# LVDSRX register map
Vendor: Texas Instruments
Peripheral module from a debugger description file (folder DM50x).
Registers are 32-bit, access per field, reset 0x0 unless marked. A register's access mark holds for its fields unless they carry their own. Offsets are as the file gives them; lines under a group give offsets from that group; [hi:lo] are bit positions; {n}, {i} and the like mark numbered series; 'fields as' and 'values as' point back to an identical list; <NAME> marks a mode.

## LVDSRX
0x00 LVDSRX_REVISION ro reset not defined — IP Revision Identifier (X.Y.R) Used by software to track features, bugs, and compatibility
  [31:0] REVISION — IP Revision
0x10 LVDSRX_SYSCONFIG — Reserved
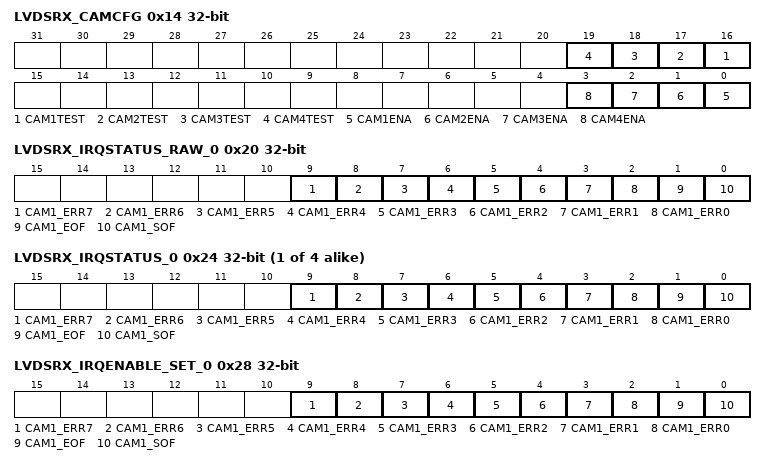
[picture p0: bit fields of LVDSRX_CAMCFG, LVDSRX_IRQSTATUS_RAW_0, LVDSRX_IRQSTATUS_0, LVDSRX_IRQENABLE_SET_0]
0x14 LVDSRX_CAMCFG — Camera port enable
  [all] fields
    0=DIABLE; 1=ENABLE
  [n+15] CAM{n}TEST rw (n=1..4) — Camera port #{n} monitor
  [n-1] CAM{n}ENA rw (n=1..4) — Camera port #{n} control
0x1C LVDSRX_IRQ_EOI — End Of Interrupt number specification
  [2:0] LINE_NUMBER rw — Software End Of Interrupt (EOI) control. Write number of interrupt output to force re-evaluation of associated pending interrupts. Write n: EOI for interrupt output associated with EOI #n.
    0=READ0 (Reads always 0 (no EOI memory)); {v}=EOI{v} (EOI for interrupt output line #{v}) (v=1..4)
0x20 LVDSRX_IRQSTATUS_RAW_0 — Per-event raw interrupt status vector, line #0. Raw status is set even if event is not enabled.
  [all] fields
    0=NOEVENT (No event pending); 1=PENDING (Event pending)
  [9] CAM1_ERR7 rw — sync detected timeout reached
  [8] CAM1_ERR6 rw — CRC error
  [7] CAM1_ERR5 rw — unexpected SOF
  [6] CAM1_ERR4 rw — unexpected SOL
  [5] CAM1_ERR3 rw — unexpected EOF
  [4] CAM1_ERR2 rw — unexpected EOL
  [3] CAM1_ERR1 rw — unexpected SOV
  [2] CAM1_ERR0 rw — EOX not received
  [1] CAM1_EOF rw — End of frame timing
  [0] CAM1_SOF rw — Start of frame timing
{0x24+0x10*i} LVDSRX_IRQSTATUS_{i} (i=0..3) — Per-event 'enabled' interrupt status vector, line #{i}. Enabled status isn't set unless event is enabled.
  [all] fields
    0=NOEVENT (No event pending); 1=PENDING (Event pending)
  [9] CAM{i+1}_ERR7 rw — sync detected timeout reached
  [8] CAM{i+1}_ERR6 rw — CRC error
  [7] CAM{i+1}_ERR5 rw — unexpected SOF
  [6] CAM{i+1}_ERR4 rw — unexpected SOL
  [5] CAM{i+1}_ERR3 rw — unexpected EOF
  [4] CAM{i+1}_ERR2 rw — unexpected EOL
  [3] CAM{i+1}_ERR1 rw — unexpected SOV
  [2] CAM{i+1}_ERR0 rw — EOX not received
  [1] CAM{i+1}_EOF rw — End of frame timing
  [0] CAM{i+1}_SOF rw — Start of frame timing
0x28 LVDSRX_IRQENABLE_SET_0 — Per-event interrupt enable bit vector Write 1 to set (enable interrupt). Readout equal to corresponding _CLR register.
  [all] fields
    0=NOACTION; 1=ENABLED (Interrupt enabled)
  [9] CAM1_ERR7 rw — sync detected timeout reached
  [8] CAM1_ERR6 rw — CRC error
  [7] CAM1_ERR5 rw — unexpected SOF
  [6] CAM1_ERR4 rw — unexpected SOL
  [5] CAM1_ERR3 rw — unexpected EOF
  [4] CAM1_ERR2 rw — unexpected EOL
  [3] CAM1_ERR1 rw — unexpected SOV
  [2] CAM1_ERR0 rw — EOX not received
  [1] CAM1_EOF rw — End of frame timing
  [0] CAM1_SOF rw — Start of frame timing
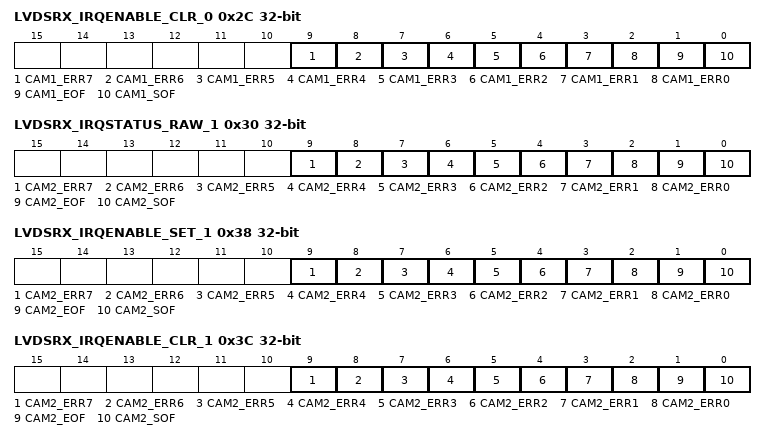
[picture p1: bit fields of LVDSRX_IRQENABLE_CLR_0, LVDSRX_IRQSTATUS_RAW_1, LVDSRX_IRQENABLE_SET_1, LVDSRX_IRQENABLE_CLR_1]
0x2C LVDSRX_IRQENABLE_CLR_0 — Per-event interrupt enable bit vector Write 1 to clear (disable interrupt). Readout equal to corresponding _SET register.
  fields as LVDSRX_IRQENABLE_SET_0
0x30 LVDSRX_IRQSTATUS_RAW_1 — Per-event raw interrupt status vector, line #1. Raw status is set even if event is not enabled.
  [all] fields
    0=NOEVENT (No event pending); 1=PENDING (Event pending)
  [9] CAM2_ERR7 rw — sync detected timeout reached
  [8] CAM2_ERR6 rw — CRC error
  [7] CAM2_ERR5 rw — unexpected SOF
  [6] CAM2_ERR4 rw — unexpected SOL
  [5] CAM2_ERR3 rw — unexpected EOF
  [4] CAM2_ERR2 rw — unexpected EOL
  [3] CAM2_ERR1 rw — unexpected SOV
  [2] CAM2_ERR0 rw — EOX not received
  [1] CAM2_EOF rw — End of frame timing
  [0] CAM2_SOF rw — Start of frame timing
0x38 LVDSRX_IRQENABLE_SET_1 — Per-event interrupt enable bit vector Write 1 to set (enable interrupt). Readout equal to corresponding _CLR register.
  [all] fields
    0=NOACTION; 1=ENABLED (Interrupt enabled)
  [9] CAM2_ERR7 rw — sync detected timeout reached
  [8] CAM2_ERR6 rw — CRC error
  [7] CAM2_ERR5 rw — unexpected SOF
  [6] CAM2_ERR4 rw — unexpected SOL
  [5] CAM2_ERR3 rw — unexpected EOF
  [4] CAM2_ERR2 rw — unexpected EOL
  [3] CAM2_ERR1 rw — unexpected SOV
  [2] CAM2_ERR0 rw — EOX not received
  [1] CAM2_EOF rw — End of frame timing
  [0] CAM2_SOF rw — Start of frame timing
0x3C LVDSRX_IRQENABLE_CLR_1 — Per-event interrupt enable bit vector Write 1 to clear (disable interrupt). Readout equal to corresponding _SET register.
  fields as LVDSRX_IRQENABLE_SET_1
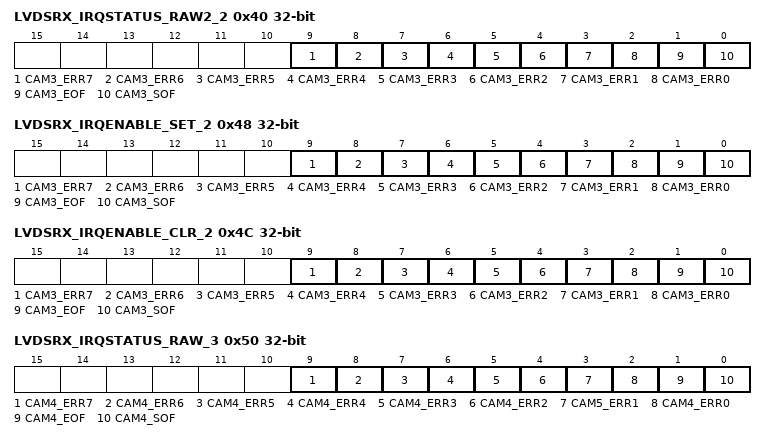
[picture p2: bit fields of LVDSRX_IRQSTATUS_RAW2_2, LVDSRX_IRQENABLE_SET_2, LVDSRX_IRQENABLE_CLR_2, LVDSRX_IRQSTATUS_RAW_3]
0x40 LVDSRX_IRQSTATUS_RAW2_2 — Per-event raw interrupt status vector, line #2. Raw status is set even if event is not enabled.
  [all] fields
    0=NOEVENT (No event pending); 1=PENDING (Event pending)
  [9] CAM3_ERR7 rw — sync detected timeout reached
  [8] CAM3_ERR6 rw — CRC error
  [7] CAM3_ERR5 rw — unexpected SOF
  [6] CAM3_ERR4 rw — unexpected SOL
  [5] CAM3_ERR3 rw — unexpected EOF
  [4] CAM3_ERR2 rw — unexpected EOL
  [3] CAM3_ERR1 rw — unexpected SOV
  [2] CAM3_ERR0 rw — EOX not received
  [1] CAM3_EOF rw — End of frame timing
  [0] CAM3_SOF rw — Start of frame timing
0x48 LVDSRX_IRQENABLE_SET_2 — Per-event interrupt enable bit vector Write 1 to set (enable interrupt). Readout equal to corresponding _CLR register.
  [9] CAM3_ERR7 rw — sync detected timeout reached
    0=NOACTION; 1=ENABLED (Interrupt enabled)
  [8] CAM3_ERR6 rw — CRC error
    0=NOACTION; 1=ENABLED (Interrupt enabled)
  [7] CAM3_ERR5 rw — unexpected SOF
    0=NOACTION; 1=ENABLED (Interrupt enabled)
  [6] CAM3_ERR4 rw — unexpected SOL
    0=NOACTION; 1=ENABLED (Interrupt enabled)
  [5] CAM3_ERR3 rw — unexpected EOF
    0=NOACTION; 1=ENABLED (Interrupt enabled)
  [4] CAM3_ERR2 rw — unexpected EOL
    0=NOACTION; 1=ENABLED (Interrupt enabled)
  [3] CAM3_ERR1 rw — unexpected SOV
    0=NOACTION; 1=ENABLED (Interrupt enabled)
  [2] CAM3_ERR0 rw — EOX not received
    0=NOACTION; 1=ENABLED (Interrupt enabled)
  [1] CAM3_EOF rw — End of frame timing
    0=NOEVENT (No event pending); 1=PENDING (Event pending)
  [0] CAM3_SOF rw — Start of frame timing
    0=NOACTION; 1=ENABLED (Interrupt enabled)
0x4C LVDSRX_IRQENABLE_CLR_2 — Per-event interrupt enable bit vector Write 1 to clear (disable interrupt). Readout equal to corresponding _SET register.
  fields as LVDSRX_IRQENABLE_SET_2
0x50 LVDSRX_IRQSTATUS_RAW_3 — Per-event raw interrupt status vector, line #3. Raw status is set even if event is not enabled.
  [all] fields
    0=NOEVENT (No event pending); 1=PENDING (Event pending)
  [9] CAM4_ERR7 rw — sync detected timeout reached
  [8] CAM4_ERR6 rw — CRC error
  [7] CAM4_ERR5 rw — unexpected SOF
  [6] CAM4_ERR4 rw — unexpected SOL
  [5] CAM4_ERR3 rw — unexpected EOF
  [4] CAM4_ERR2 rw — unexpected EOL
  [3] CAM5_ERR1 rw — unexpected SOV
  [2] CAM4_ERR0 rw — EOX not received
  [1] CAM4_EOF rw — End of frame timing
  [0] CAM4_SOF rw — Start of frame timing
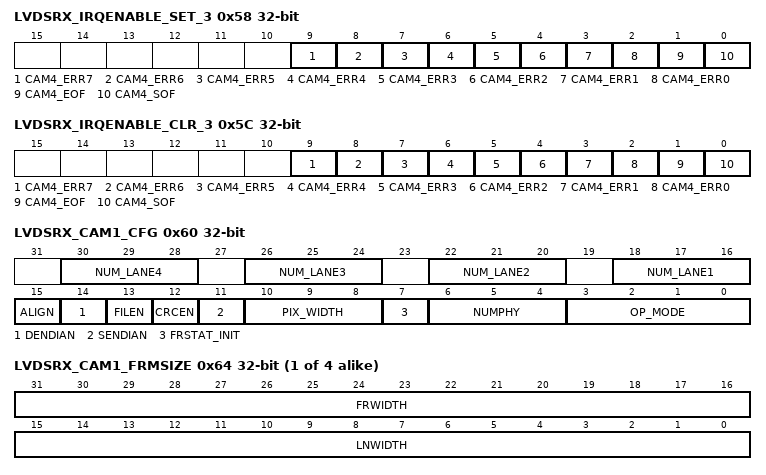
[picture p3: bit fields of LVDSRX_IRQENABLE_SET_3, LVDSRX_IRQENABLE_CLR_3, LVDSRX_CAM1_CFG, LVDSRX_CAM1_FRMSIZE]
0x58 LVDSRX_IRQENABLE_SET_3 — Per-event interrupt enable bit vector Write 1 to set (enable interrupt). Readout equal to corresponding _CLR register.
  [all] fields
    0=NOACTION; 1=ENABLED (Interrupt enabled)
  [9] CAM4_ERR7 rw — sync detected timeout reached
  [8] CAM4_ERR6 rw — CRC error
  [7] CAM4_ERR5 rw — unexpected SOF
  [6] CAM4_ERR4 rw — unexpected SOL
  [5] CAM4_ERR3 rw — unexpected EOF
  [4] CAM4_ERR2 rw — unexpected EOL
  [3] CAM4_ERR1 rw — unexpected SOV
  [2] CAM4_ERR0 rw — EOX not received
  [1] CAM4_EOF rw — End of frame timing
  [0] CAM4_SOF rw — Start of frame timing
0x5C LVDSRX_IRQENABLE_CLR_3 — Per-event interrupt enable bit vector Write 1 to clear (disable interrupt). Readout equal to corresponding _SET register.
  fields as LVDSRX_IRQENABLE_SET_3
0x60 LVDSRX_CAM1_CFG — CAM output port #1 configuration This register associate one bit for each context in order to enable/disable each context individually.
  [30:28] NUM_LANE4 rw — Number of lanes of PHY4 when NUM_PHY 3
  [26:24] NUM_LANE3 rw — Number of lanes of PHY3 when NUM_PHY 2
  [22:20] NUM_LANE2 rw — Number of lanes of PHY2 when NUM_PHY 1
  [18:16] NUM_LANE1 rw — Number of lanes of PHY1
  [15] ALIGN rw — MSB, LSB alignment for output pixel data 0: LSB align 1: MSB align
  [14] DENDIAN rw — Transmit format of none SYNC area 0: Little endian 1: big endian
  [13] FILEN rw — 1: Transmitted data includes filier codes
  [12] CRCEN rw — 1: enables checking of the checksum transmitted in the APTINA HiSPi data stream
  [11] SENDIAN rw — Transmit format of SYNC area 0: Little endian 1: big endian
  [10:8] PIX_WIDTH rw — Word width of recovered parallel data. 0: 8-BITS 1: 10-BITS 2: 12-BITS 3: 14-BITS 4: 16-BITS 5-7: RESERVED
  [7] FRSTAT_INIT rw — Specifies Initial frame state in mode2,mode4,mod5 and mode8. If the first comming sync code is knows as start of frame(SOF) when enable decoding, it is able to write 0. If sync code is unknown, should write 1. In other mode, should be coded 0.
  [6:4] NUMPHY rw — Number of PHYs 0 ~ 4 is available
  [3:0] OP_MODE rw — Protocol selection 0: Serial LVDS mode 1 1: Serial LVDS mode 2 2: Serial LVDS mode 3 3: Serial LVDS mode 4 4: Serial LVDS mode 5 5: Serial LVDS mode 6 6: Serial LVDS mode 7 7: Serial LVDS mode 8 8: Serial LVDS mode 9 9-15: Reserved
{0x44+0x20*i} LVDSRX_CAM{i}_FRMSIZE rw (i=1..4) — CAM port #{i} frame X*Y width
  [31:16] FRWIDTH — Frame size in number of image lines
  [15:0] LNWIDTH — Image line width in number of data words
{0x48+0x20*i} LVDSRX_CAM{i}_MAXWIDTH reset 0xFFFF (i=1..4) — CAM port #{i} maximum line width
  [15:0] MAXWIDTH rw — The maximum line width expected in number of pixels.
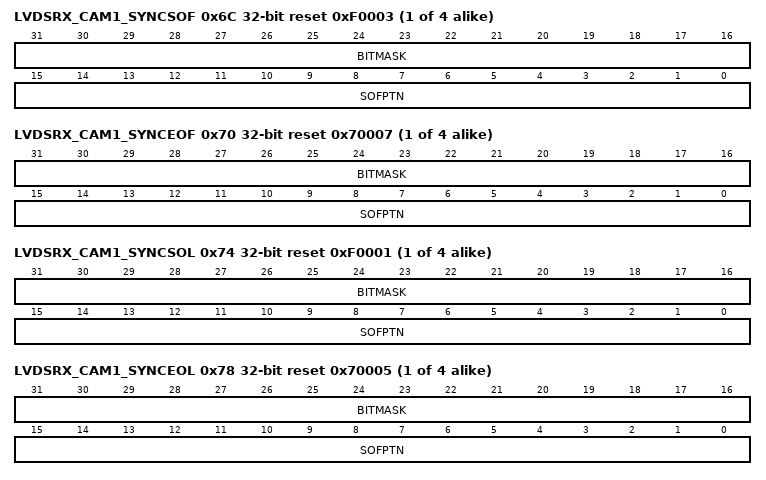
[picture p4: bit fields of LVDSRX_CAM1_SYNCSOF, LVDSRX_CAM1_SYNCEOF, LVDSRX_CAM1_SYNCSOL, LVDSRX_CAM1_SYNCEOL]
{0x4C+0x20*i} LVDSRX_CAM{i}_SYNCSOF rw reset 0xF0003 (i=1..4) — Specifies SYNC pattern
  [31:16] BITMASK — Specifies the mask bit to be compared. Ex.) set 0x3ff when does pattern matching for low 10bit.
  [15:0] SOFPTN — Specifies SOF(Start Of Frame) sync pattern
{0x50+0x20*i} LVDSRX_CAM{i}_SYNCEOF rw reset 0x70007 (i=1..4) — Specifies SYNC pattern
  [31:16] BITMASK — Specifies the mask bit to be compared. Ex.) set 0x3ff when does pattern matching for low 10bit.
  [15:0] SOFPTN — Specifies SOF(End Of Frame) sync pattern
{0x54+0x20*i} LVDSRX_CAM{i}_SYNCSOL rw reset 0xF0001 (i=1..4) — Specifies SYNC pattern
  [31:16] BITMASK — Specifies the mask bit to be compared. Ex.) set 0x3ff when does pattern matching for low 10bit.
  [15:0] SOFPTN — Specifies SOF(Start Of Line) sync pattern
{0x58+0x20*i} LVDSRX_CAM{i}_SYNCEOL rw reset 0x70005 (i=1..4) — Specifies SYNC pattern
  [31:16] BITMASK — Specifies the mask bit to be compared. Ex.) set 0x3ff when does pattern matching for low 10bit.
  [15:0] SOFPTN — Specifies SOF(End Of Line) sync pattern
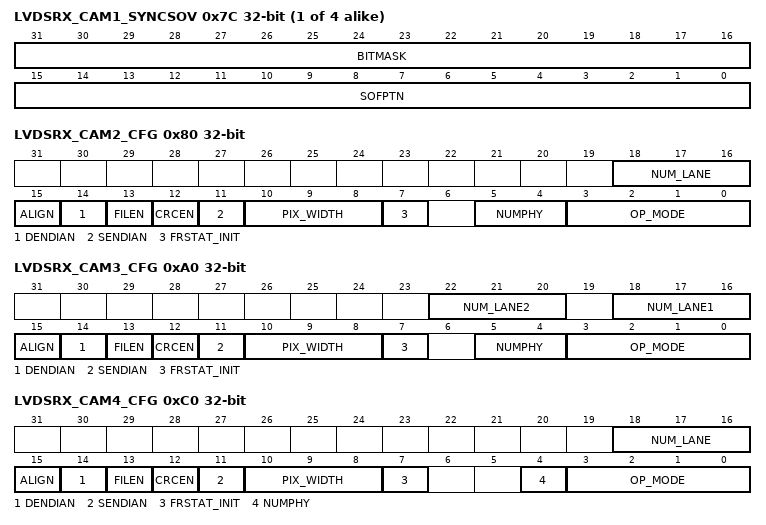
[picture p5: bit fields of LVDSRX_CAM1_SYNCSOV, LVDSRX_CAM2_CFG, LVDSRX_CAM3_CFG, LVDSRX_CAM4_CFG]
{0x5C+0x20*i} LVDSRX_CAM{i}_SYNCSOV rw (i=1..4) — Specifies SYNC pattern
  [31:16] BITMASK — Specifies the mask bit to be compared. Ex.) set 0x3ff when does pattern matching for low 10bit.
  [15:0] SOFPTN — Specifies SOF(Start Of V-blanking) sync pattern
0x80 LVDSRX_CAM2_CFG — CAM output port #2 configuration This register associate one bit for each context in order to enable/disable each context individually.
  [18:16] NUM_LANE rw — Number of lanes of PHY2
  [15] ALIGN rw — MSB, LSB alignment for output pixel data 0: LSB align 1: MSB align
  [14] DENDIAN rw — Transmit format of none SYNC area 0: Little endian 1: big endian
  [13] FILEN rw — 1: Transmitted data includes filier codes
  [12] CRCEN rw — 1: enables checking of the checksum transmitted in the APTINA HiSPi data stream
  [11] SENDIAN rw — Transmit format of SYNC area 0: Little endian 1: big endian
  [10:8] PIX_WIDTH rw — Word width of recovered parallel data. 0: 8-BITS 1: 10-BITS 2: 12-BITS 3: 14-BITS 4: 16-BITS 5-7: RESERVED
  [7] FRSTAT_INIT rw — Specifies Initial frame state in mode2,mode4,mod5 and mode8. If the first comming sync code is knows as start of frame(SOF) when enable decoding, it is able to write 0. If sync code is unknown, should write 1. In other mode, should be coded 0.
  [5:4] NUMPHY rw — Number of PHYs 0 ~ 1 is available
  [3:0] OP_MODE rw — Protocol selection 0: Serial LVDS mode 1 1: Serial LVDS mode 2 2: Serial LVDS mode 3 3: Serial LVDS mode 4 4: Serial LVDS mode 5 5: Serial LVDS mode 6 6: Serial LVDS mode 7 7: Serial LVDS mode 8 8: Serial LVDS mode 9 9-15: Reserved
0xA0 LVDSRX_CAM3_CFG — CAM output port #3 configuration This register associate one bit for each context in order to enable/disable each context individually.
  [22:20] NUM_LANE2 rw — Number of lanes of PHY4 when NUM_PHY 1
  [18:16] NUM_LANE1 rw — Number of lanes of PHY3
  [15] ALIGN rw — MSB, LSB alignment for output pixel data 0: LSB align 1: MSB align
  [14] DENDIAN rw — Transmit format of none SYNC area 0: Little endian 1: big endian
  [13] FILEN rw — 1: Transmitted data includes filier codes
  [12] CRCEN rw — 1: enables checking of the checksum transmitted in the APTINA HiSPi data stream
  [11] SENDIAN rw — Transmit format of SYNC area 0: Little endian 1: big endian
  [10:8] PIX_WIDTH rw — Word width of recovered parallel data. 0: 8-BITS 1: 10-BITS 2: 12-BITS 3: 14-BITS 4: 16-BITS 5-7: RESERVED
  [7] FRSTAT_INIT rw — Specifies Initial frame state in mode2,mode4,mod5 and mode8. If the first comming sync code is knows as start of frame(SOF) when enable decoding, it is able to write 0. If sync code is unknown, should write 1. In other mode, should be coded 0.
  [5:4] NUMPHY rw — Number of PHYs 0,1, 2 is available
  [3:0] OP_MODE rw — Protocol selection 0: Serial LVDS mode 1 1: Serial LVDS mode 2 2: Serial LVDS mode 3 3: Serial LVDS mode 4 4: Serial LVDS mode 5 5: Serial LVDS mode 6 6: Serial LVDS mode 7 7: Serial LVDS mode 8 8: Serial LVDS mode 9 9-15: Reserved
0xC0 LVDSRX_CAM4_CFG — CAM output port #4 configuration This register associate one bit for each context in order to enable/disable each context individually.
  [18:16] NUM_LANE rw — Number of lanes of PHY4
  [15] ALIGN rw — MSB, LSB alignment for output pixel data 0: LSB align 1: MSB align
  [14] DENDIAN rw — Transmit format of none SYNC area 0: Little endian 1: big endian
  [13] FILEN rw — 1: Transmitted data includes filier codes
  [12] CRCEN rw — 1: enables checking of the checksum transmitted in the APTINA HiSPi data stream
  [11] SENDIAN rw — Transmit format of SYNC area 0: Little endian 1: big endian
  [10:8] PIX_WIDTH rw — Word width of recovered parallel data. 0: 8-BITS 1: 10-BITS 2: 12-BITS 3: 14-BITS 4: 16-BITS 5-7: RESERVED
  [7] FRSTAT_INIT rw — Specifies Initial frame state in mode2,mode4,mod5 and mode8. If the first comming sync code is knows as start of frame(SOF) when enable decoding, it is able to write 0. If sync code is unknown, should write 1. In other mode, should be coded 0.
  [4] NUMPHY rw — Number of PHYs 0,1 is available
  [3:0] OP_MODE rw — Protocol selection 0: Serial LVDS mode 1 1: Serial LVDS mode 2 2: Serial LVDS mode 3 3: Serial LVDS mode 4 4: Serial LVDS mode 5 5: Serial LVDS mode 6 6: Serial LVDS mode 7 7: Serial LVDS mode 8 8: Serial LVDS mode 9 9-13: Reserved 14: CMOS parallel IF (CCIR656 embeded sync) 15: CMOS parallel IF (extenal HSYNC/VSYNC) When in mode 14,15, the input parallel i/f signals go to CAM #4 output port.)
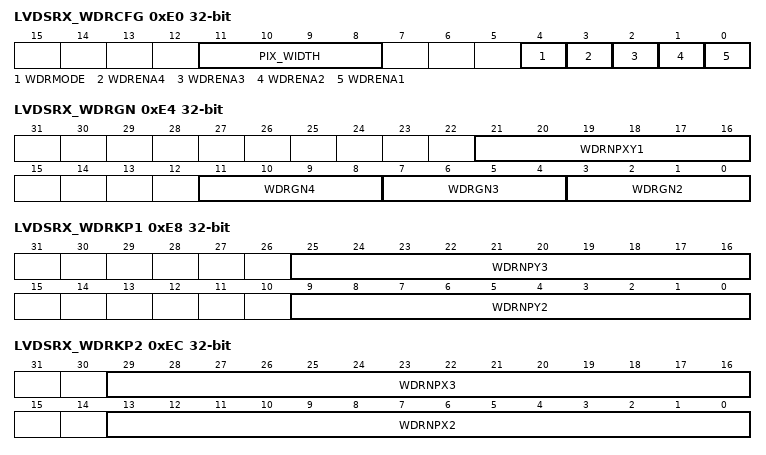
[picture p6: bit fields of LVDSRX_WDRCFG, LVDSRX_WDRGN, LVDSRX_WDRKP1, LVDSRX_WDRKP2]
0xE0 LVDSRX_WDRCFG
  [11:8] PIX_WIDTH rw — Word width after de-companded. 0: 12-BITS 1: 13-BITS 2: 14-BITS 3: 15-BITS 4: 16-BITS 5: 17-BITS 6: 18-BITS 7: 19-BITS 8: 20-BITS 9-15: RESERVED
  [4] WDRMODE rw — WDR mode select 0: de-companding 1: bit interlaced format Not alloweed to code 1 to WDRENA3 and WDRENA4 at the same time.
  [3] WDRENA4 rw — WDR mode enable for CAM port #4. 0: disable 1: enable WDR function Not alloweed to code 1 to WDRENA3 and WDRENA4 at the same time.
  [2] WDRENA3 rw — WDR mode enable for CAM port #3. 0: disable 1: enable WDR function Not alloweed to code 1 to WDRENA3 and WDRENA4 at the same time.
  [1] WDRENA2 rw — WDR mode enable for CAM port #2. 0: disable 1: enable WDR function Not alloweed to code 1 to WDRENA1 and WDRENA2 at the same time.
  [0] WDRENA1 rw — WDR mode enable for CAM port #1. 0: disable 1: enable WDR function Not alloweed to code 1 to WDRENA1 and WDRENA2 at the same time.
0xE4 LVDSRX_WDRGN — WDR gain configuration
  [21:16] WDRNPXY1 rw — Specifies the pixel level for area #1 knee point inX/ Y axis. Level = WDRNPXY1 * 256
  [11:8] WDRGN4 rw — Specifies the gain for area #4 Gain = 1/2^WDRGN4
  [7:4] WDRGN3 rw — Specifies the gain for area #3 Gain = 1/2^WDRGN3
  [3:0] WDRGN2 rw — Specifies the gain for area #2 Gain = 1/2^WDRGN2
0xE8 LVDSRX_WDRKP1 — WDR knee point configuration
  [25:16] WDRNPY3 rw — Specifies the pixel level for area #3 knee point in Y axis. Level = WDRNPY3 * 256
  [9:0] WDRNPY2 rw — Specifies the pixel level for area #2 knee point in Y axis. Level = WDRNPY2 * 256
0xEC LVDSRX_WDRKP2
  [29:16] WDRNPX3 rw — Specifies the pixel level for area #3 knee point in X axis. Level = WDRNPX3
  [13:0] WDRNPX2 rw — Specifies the pixel level for area #2 knee point in X axis. Level = WDRNPX2
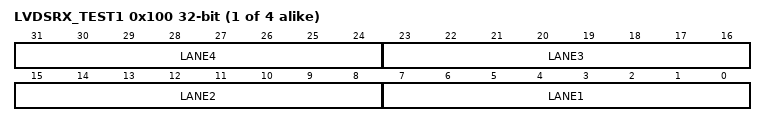
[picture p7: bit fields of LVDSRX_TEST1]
{0xFC+4i} LVDSRX_TEST{i} ro (i=1..4) — When.CAM{i}TEST=1, PHY #{i} data (8bitx4 lanes) can be monitored by this register.
  [8n-1:8n-8] LANE{n} (n=1..4) — lane #{n} byte data
